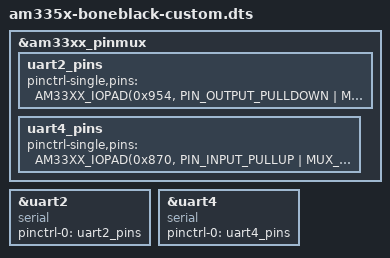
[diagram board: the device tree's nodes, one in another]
#include "am335x-boneblack.dts"

&am33xx_pinmux {
    uart2_pins: uart2_pins { //this allows muxing to enable and configure uart2 on BBB (Pins P9_21 P9_22)
        pinctrl-single,pins = < 
            AM33XX_IOPAD(0x954, PIN_OUTPUT_PULLDOWN | MUX_MODE1) //0X954 = p9_22
            AM33XX_IOPAD(0x950, PIN_OUTPUT_PULLUP | MUX_MODE1)   //0X950 = p9_21
            >;
    };
    
    // Enabling UART4
	uart4_pins: uart4_pins {//p9_11 & 13
	pinctrl-single,pins = <
		AM33XX_IOPAD(0x870, PIN_INPUT_PULLUP | MUX_MODE6)
		AM33XX_IOPAD(0x874, PIN_OUTPUT_PULLDOWN | MUX_MODE6)
		>;
	};

};//end am33xx_pinmux

&uart2 {
    compatible = "serial";      //for kernel to identify compatible device driver
    status = "okay";            //enabled
    pinctrl-names = "default";  //default names for pins
    pinctrl-0 = <&uart2_pins>;
};

&uart4 {
    compatible = "serial";      //for kernel to identify compatible device driver
    status = "okay";            //enabled
    pinctrl-names = "default";  //default names for pins
    pinctrl-0 = <&uart4_pins>;
};


